VERSION "VehicleGPT prototype"

NS_ :

BS_:
BU_: VEHICLE

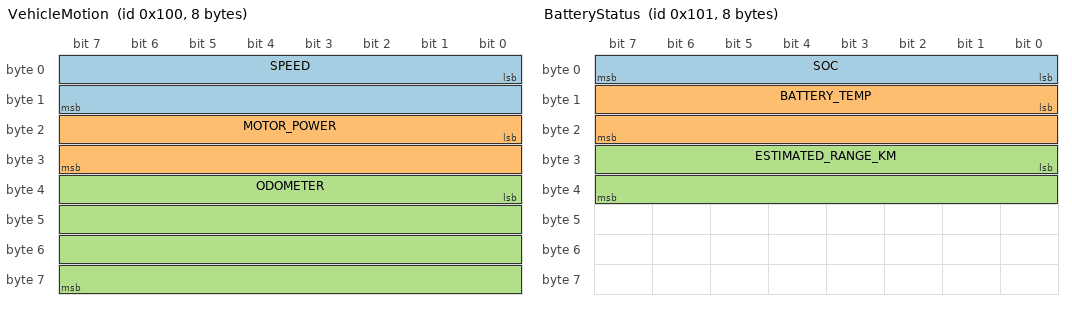
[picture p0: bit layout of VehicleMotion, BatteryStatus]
BO_ 256 VehicleMotion: 8 VEHICLE
 SG_ SPEED : 0|16@1+ (0.01,0) [0|250] "km/h" VEHICLE
 SG_ MOTOR_POWER : 16|16@1+ (0.1,0) [0|500] "kW" VEHICLE
 SG_ ODOMETER : 32|32@1+ (0.1,0) [0|1000000] "km" VEHICLE

BO_ 257 BatteryStatus: 8 VEHICLE
 SG_ SOC : 0|8@1+ (0.5,0) [0|100] "%" VEHICLE
 SG_ BATTERY_TEMP : 8|16@1+ (0.1,-40) [-40|200] "degC" VEHICLE
 SG_ ESTIMATED_RANGE_KM : 24|16@1+ (1,0) [0|1000] "km" VEHICLE

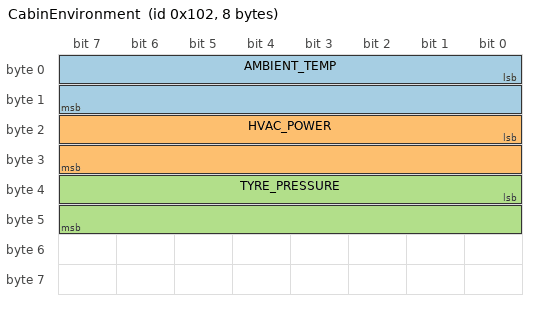
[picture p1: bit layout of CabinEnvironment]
BO_ 258 CabinEnvironment: 8 VEHICLE
 SG_ AMBIENT_TEMP : 0|16@1+ (0.1,-40) [-40|100] "degC" VEHICLE
 SG_ HVAC_POWER : 16|16@1+ (0.1,0) [0|20] "kW" VEHICLE
 SG_ TYRE_PRESSURE : 32|16@1+ (0.001,0) [0|10] "bar" VEHICLE

BO_ 259 DriverAssistance: 8 VEHICLE
 SG_ ADAS_STATE : 0|8@1+ (1,0) [0|3] "enum" VEHICLE
